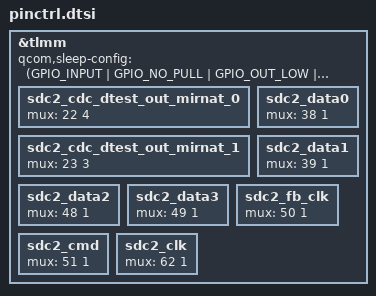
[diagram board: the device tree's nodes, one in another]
#include "gpio-dt.h"

/**
 *
 * NOTE: Every Dev team has to uncomment the respective PIN configuratoin.
 *
 */
&tlmm {
 // qup1_se0_l0: qup1_se0_l0 {
 // mux = <0 1>;
 // };
 // ibi_i3c_qup1_se0_sda: ibi_i3c_qup1_se0_sda {
 // mux = <0 2>;
 // };
 // qup1_se0_l1: qup1_se0_l1 {
 // mux = <1 1>;
 // };
 // ibi_i3c_qup1_se0_scl: ibi_i3c_qup1_se0_scl {
 // mux = <1 2>;
 // };
 // qup1_se0_l2: qup1_se0_l2 {
 // mux = <2 1>;
 // };
 // qup1_se0_l3: qup1_se0_l3 {
 // mux = <3 1>;
 // };
 // qup0_se1_l0: qup0_se1_l0 {
 // mux = <4 1>;
 // };
 // ibi_i3c_qup0_se1_sda: ibi_i3c_qup0_se1_sda {
 // mux = <4 2>;
 // };
 // gcc_gp3_clk_mirb: gcc_gp3_clk_mirb {
 // mux = <4 3>;
 // };
 // qdss_gpio_tracedata_loca_15: qdss_gpio_tracedata_loca_15 {
 // mux = <4 4>;
 // };
 // qup0_se1_l1: qup0_se1_l1 {
 // mux = <5 1>;
 // };
 // ibi_i3c_qup0_se1_scl: ibi_i3c_qup0_se1_scl {
 // mux = <5 2>;
 // };
 // qdss_gpio_tracedata_loca_13: qdss_gpio_tracedata_loca_13 {
 // mux = <5 3>;
 // };
 // qup0_se1_l2: qup0_se1_l2 {
 // mux = <6 1>;
 // };
 // dbg_bus_out_loca_31: dbg_bus_out_loca_31 {
 // mux = <6 2>;
 // };
 // phase_flag_status_loc_31: phase_flag_status_loc_31 {
 // mux = <6 3>;
 // };
 // qup0_se1_l3: qup0_se1_l3 {
 // mux = <7 1>;
 // };
 // dbg_bus_out_loca_30: dbg_bus_out_loca_30 {
 // mux = <7 2>;
 // };
 // phase_flag_status_loc_30: phase_flag_status_loc_30 {
 // mux = <7 3>;
 // };
 // qup0_se2_l0: qup0_se2_l0 {
 // mux = <8 1>;
 // };
 // dbg_bus_out_loca_29: dbg_bus_out_loca_29 {
 // mux = <8 2>;
 // };
 // phase_flag_status_loc_29: phase_flag_status_loc_29 {
 // mux = <8 3>;
 // };
 // qup0_se2_l1: qup0_se2_l1 {
 // mux = <9 1>;
 // };
 // dbg_bus_out_loca_28: dbg_bus_out_loca_28 {
 // mux = <9 2>;
 // };
 // phase_flag_status_loc_28: phase_flag_status_loc_28 {
 // mux = <9 3>;
 // };
 // qup0_se2_l2: qup0_se2_l2 {
 // mux = <10 1>;
 // };
 // dbg_bus_out_loca_27: dbg_bus_out_loca_27 {
 // mux = <10 2>;
 // };
 // phase_flag_status_loc_27: phase_flag_status_loc_27 {
 // mux = <10 3>;
 // };
 // qup0_se2_l3: qup0_se2_l3 {
 // mux = <11 1>;
 // };
 // dbg_bus_out_loca_26: dbg_bus_out_loca_26 {
 // mux = <11 2>;
 // };
 // phase_flag_status_loc_26: phase_flag_status_loc_26 {
 // mux = <11 3>;
 // };
 // cci_timer2: cci_timer2 {
 // mux = <12 1>;
 // };
 // qup0_se3_l0: qup0_se3_l0 {
 // mux = <12 2>;
 // };
 // qup0_se1_l4: qup0_se1_l4 {
 // mux = <12 3>;
 // };
 // dbg_bus_out_loca_25: dbg_bus_out_loca_25 {
 // mux = <12 4>;
 // };
 // phase_flag_status_loc_25: phase_flag_status_loc_25 {
 // mux = <12 5>;
 // };
 // qdss_gpio_tracectl_loca: qdss_gpio_tracectl_loca {
 // mux = <12 6>;
 // };
 // cci_timer3: cci_timer3 {
 // mux = <13 1>;
 // };
 // qup0_se3_l1: qup0_se3_l1 {
 // mux = <13 2>;
 // };
 // qup0_se1_l5: qup0_se1_l5 {
 // mux = <13 3>;
 // };
 // dbg_bus_out_loca_24: dbg_bus_out_loca_24 {
 // mux = <13 4>;
 // };
 // phase_flag_status_loc_24: phase_flag_status_loc_24 {
 // mux = <13 5>;
 // };
 // qdss_gpio_traceclk_loca: qdss_gpio_traceclk_loca {
 // mux = <13 6>;
 // };
 // cci_timer1: cci_timer1 {
 // mux = <14 1>;
 // };
 // cci_async_in2: cci_async_in2 {
 // mux = <14 2>;
 // };
 // qup0_se3_l2: qup0_se3_l2 {
 // mux = <14 3>;
 // };
 // qup0_se1_l6: qup0_se1_l6 {
 // mux = <14 4>;
 // };
 // dbg_bus_out_loca_23: dbg_bus_out_loca_23 {
 // mux = <14 5>;
 // };
 // phase_flag_status_loc_23: phase_flag_status_loc_23 {
 // mux = <14 6>;
 // };
 // cci_timer4: cci_timer4 {
 // mux = <15 1>;
 // };
 // cci_async_in1: cci_async_in1 {
 // mux = <15 2>;
 // };
 // qup0_se3_l3: qup0_se3_l3 {
 // mux = <15 3>;
 // };
 // tgu_ch2_trigout: tgu_ch2_trigout {
 // mux = <15 4>;
 // };
 // dbg_bus_out_loca_22: dbg_bus_out_loca_22 {
 // mux = <15 5>;
 // };
 // phase_flag_status_loc_22: phase_flag_status_loc_22 {
 // mux = <15 6>;
 // };
 // qdss_gpio_tracedata_loca_14: qdss_gpio_tracedata_loca_14 {
 // mux = <15 7>;
 // };
 // qup0_se4_l0: qup0_se4_l0 {
 // mux = <16 1>;
 // };
 // ibi_i3c_qup0_se4_sda: ibi_i3c_qup0_se4_sda {
 // mux = <16 2>;
 // };
 // dbg_bus_out_loca_21: dbg_bus_out_loca_21 {
 // mux = <16 3>;
 // };
 // phase_flag_status_loc_21: phase_flag_status_loc_21 {
 // mux = <16 4>;
 // };
 // qup0_se4_l1: qup0_se4_l1 {
 // mux = <17 1>;
 // };
 // ibi_i3c_qup0_se4_scl: ibi_i3c_qup0_se4_scl {
 // mux = <17 2>;
 // };
 // dbg_bus_out_loca_20: dbg_bus_out_loca_20 {
 // mux = <17 3>;
 // };
 // phase_flag_status_loc_20: phase_flag_status_loc_20 {
 // mux = <17 4>;
 // };
 // qup0_se4_l2: qup0_se4_l2 {
 // mux = <18 1>;
 // };
 // dbg_bus_out_loca_19: dbg_bus_out_loca_19 {
 // mux = <18 2>;
 // };
 // phase_flag_status_loc_19: phase_flag_status_loc_19 {
 // mux = <18 3>;
 // };
 // qup0_se4_l3: qup0_se4_l3 {
 // mux = <19 1>;
 // };
 // gp_pdm_mira_0: gp_pdm_mira_0 {
 // mux = <19 2>;
 // };
 // dbg_bus_out_loca_18: dbg_bus_out_loca_18 {
 // mux = <19 3>;
 // };
 // phase_flag_status_loc_18: phase_flag_status_loc_18 {
 // mux = <19 4>;
 // };
 // qup0_se5_l0: qup0_se5_l0 {
 // mux = <20 1>;
 // };
 // cci_i2c_sda3: cci_i2c_sda3 {
 // mux = <20 2>;
 // };
 // qup0_se2_l4: qup0_se2_l4 {
 // mux = <20 3>;
 // };
 // gp_pdm_mira_1: gp_pdm_mira_1 {
 // mux = <20 4>;
 // };
 // dbg_bus_out_loca_17: dbg_bus_out_loca_17 {
 // mux = <20 5>;
 // };
 // phase_flag_status_loc_17: phase_flag_status_loc_17 {
 // mux = <20 6>;
 // };
 // qup0_se5_l1: qup0_se5_l1 {
 // mux = <21 1>;
 // };
 // cci_i2c_scl3: cci_i2c_scl3 {
 // mux = <21 2>;
 // };
 // qup0_se2_l5: qup0_se2_l5 {
 // mux = <21 3>;
 // };
 // gp_pdm_mira_2: gp_pdm_mira_2 {
 // mux = <21 4>;
 // };
 // dbg_bus_out_loca_16: dbg_bus_out_loca_16 {
 // mux = <21 5>;
 // };
 // phase_flag_status_loc_16: phase_flag_status_loc_16 {
 // mux = <21 6>;
 // };
 // qup0_se5_l2: qup0_se5_l2 {
 // mux = <22 1>;
 // };
 // qup0_se2_l6: qup0_se2_l6 {
 // mux = <22 2>;
 // };
 // jitter_bist_ref_clk: jitter_bist_ref_clk {
 // mux = <22 3>;
 // };
 sdc2_cdc_dtest_out_mirnat_0: sdc2_cdc_dtest_out_mirnat_0 {
 mux = <22 4>;
  };
 // vsense_trigger_mirnat: vsense_trigger_mirnat {
 // mux = <22 5>;
 // };
 // atest_usb0_atereset_mirnat: atest_usb0_atereset_mirnat {
 // mux = <22 6>;
 // };
 // ddr_pxi0_test_tri_mirnat: ddr_pxi0_test_tri_mirnat {
 // mux = <22 7>;
 // };
 // qup0_se5_l3: qup0_se5_l3 {
 // mux = <23 1>;
 // };
 // pll_bist_sync: pll_bist_sync {
 // mux = <23 2>;
 // };
 sdc2_cdc_dtest_out_mirnat_1: sdc2_cdc_dtest_out_mirnat_1 {
 mux = <23 3>;
  };
 // atest_usb0_testdataout0_mirnat_0: atest_usb0_testdataout0_mirnat_0 {
 // mux = <23 4>;
 // };
 // ddr_pxi0_test_done_mirnat: ddr_pxi0_test_done_mirnat {
 // mux = <23 5>;
 // };
 // qup0_se6_l0: qup0_se6_l0 {
 // mux = <24 1>;
 // };
 // ibi_i3c_qup0_se6_sda: ibi_i3c_qup0_se6_sda {
 // mux = <24 2>;
 // };
 // tgu_ch0_trigout: tgu_ch0_trigout {
 // mux = <24 3>;
 // };
 // qdss_cti_trig0_out_mira: qdss_cti_trig0_out_mira {
 // mux = <24 4>;
 // };
 // atest_usb0_testdataout0_mirnat_1: atest_usb0_testdataout0_mirnat_1 {
 // mux = <24 5>;
 // };
 // ddr_pxi1_test_tri_mirnat: ddr_pxi1_test_tri_mirnat {
 // mux = <24 6>;
 // };
 // qup0_se6_l1: qup0_se6_l1 {
 // mux = <25 1>;
 // };
 // ibi_i3c_qup0_se6_scl: ibi_i3c_qup0_se6_scl {
 // mux = <25 2>;
 // };
 // tgu_ch1_trigout: tgu_ch1_trigout {
 // mux = <25 3>;
 // };
 // qdss_cti_trig1_out_mira: qdss_cti_trig1_out_mira {
 // mux = <25 4>;
 // };
 // atest_usb0_testdataout0_mirnat_2: atest_usb0_testdataout0_mirnat_2 {
 // mux = <25 5>;
 // };
 // ddr_pxi1_test_done_mirnat: ddr_pxi1_test_done_mirnat {
 // mux = <25 6>;
 // };
 // qup0_se6_l2: qup0_se6_l2 {
 // mux = <26 1>;
 // };
 // pll_clk_aux: pll_clk_aux {
 // mux = <26 2>;
 // };
 // atest_usb0_testdataout0_mirnat_3: atest_usb0_testdataout0_mirnat_3 {
 // mux = <26 3>;
 // };
 // qup0_se6_l3: qup0_se6_l3 {
 // mux = <27 1>;
 // };
 // gp_mn: gp_mn {
 // mux = <27 2>;
 // };
 // tsense_pwm1_out_mirnat: tsense_pwm1_out_mirnat {
 // mux = <27 3>;
 // };
 // tsense_pwm2_out_mirnat: tsense_pwm2_out_mirnat {
 // mux = <27 4>;
 // };
 // tsense_pwm3_out_mirnat: tsense_pwm3_out_mirnat {
 // mux = <27 5>;
 // };
 // qup0_se7_l0: qup0_se7_l0 {
 // mux = <28 1>;
 // };
 // aoss_cti_debug_data0: aoss_cti_debug_data0 {
 // mux = <28 2>;
 // };
 // tgu_ch3_trigout: tgu_ch3_trigout {
 // mux = <28 3>;
 // };
 // qup0_se7_l1: qup0_se7_l1 {
 // mux = <29 1>;
 // };
 // aoss_cti_debug_data1: aoss_cti_debug_data1 {
 // mux = <29 2>;
 // };
 // sd_write_protect: sd_write_protect {
 // mux = <29 3>;
 // };
 // qup0_se7_l2: qup0_se7_l2 {
 // mux = <30 1>;
 // };
 // cci_async_in0: cci_async_in0 {
 // mux = <30 2>;
 // };
 // aoss_cti_debug_data2: aoss_cti_debug_data2 {
 // mux = <30 3>;
 // };
 // qup0_se7_l3: qup0_se7_l3 {
 // mux = <31 1>;
 // };
 // aoss_cti_debug_data3: aoss_cti_debug_data3 {
 // mux = <31 2>;
 // };
 // qup1_se5_l0: qup1_se5_l0 {
 // mux = <32 1>;
 // };
 // gcc_gp1_clk_mira: gcc_gp1_clk_mira {
 // mux = <32 2>;
 // };
 // gnss_adc_dtest_l1_mirnat_0: gnss_adc_dtest_l1_mirnat_0 {
 // mux = <32 3>;
 // };
 // ddr_pxi2_test_done_mirnat: ddr_pxi2_test_done_mirnat {
 // mux = <32 4>;
 // };
 // qup1_se5_l1: qup1_se5_l1 {
 // mux = <33 1>;
 // };
 // gcc_gp2_clk_mira: gcc_gp2_clk_mira {
 // mux = <33 2>;
 // };
 // gnss_adc_dtest_l1_mirnat_1: gnss_adc_dtest_l1_mirnat_1 {
 // mux = <33 3>;
 // };
 // ddr_pxi2_test_tri_mirnat: ddr_pxi2_test_tri_mirnat {
 // mux = <33 4>;
 // };
 // qup1_se5_l2: qup1_se5_l2 {
 // mux = <34 1>;
 // };
 // gcc_gp3_clk_mira: gcc_gp3_clk_mira {
 // mux = <34 2>;
 // };
 // dbg_out_clk: dbg_out_clk {
 // mux = <34 3>;
 // };
 // gnss_adc_dtest_l5_mirnat_0: gnss_adc_dtest_l5_mirnat_0 {
 // mux = <34 4>;
 // };
 // ddr_pxi3_test_done_mirnat: ddr_pxi3_test_done_mirnat {
 // mux = <34 5>;
 // };
 // qup1_se5_l3: qup1_se5_l3 {
 // mux = <35 1>;
 // };
 // gcc_gp1_clk_mirb: gcc_gp1_clk_mirb {
 // mux = <35 2>;
 // };
 // gnss_adc_dtest_l5_mirnat_1: gnss_adc_dtest_l5_mirnat_1 {
 // mux = <35 3>;
 // };
 // ddr_pxi3_test_tri_mirnat: ddr_pxi3_test_tri_mirnat {
 // mux = <35 4>;
 // };
 // qup1_se1_l0: qup1_se1_l0 {
 // mux = <36 1>;
 // };
 // ibi_i3c_qup1_se1_sda: ibi_i3c_qup1_se1_sda {
 // mux = <36 2>;
 // };
 // qup1_se1_l2: qup1_se1_l2 {
 // mux = <36 3>;
 // };
 // gcc_gp2_clk_mirb: gcc_gp2_clk_mirb {
 // mux = <36 4>;
 // };
 // qup1_se1_l1: qup1_se1_l1 {
 // mux = <37 1>;
 // };
 // ibi_i3c_qup1_se1_scl: ibi_i3c_qup1_se1_scl {
 // mux = <37 2>;
 // };
 // qup1_se1_l3: qup1_se1_l3 {
 // mux = <37 3>;
 // };
 sdc2_data0: sdc2_data0 {
    mux = <38 1>;
  };
 sdc2_data1: sdc2_data1 {
    mux = <39 1>;
  };
 // qup1_se2_l0: qup1_se2_l0 {
 // mux = <40 1>;
 // };
 // dbg_bus_out_loca_13: dbg_bus_out_loca_13 {
 // mux = <40 2>;
 // };
 // phase_flag_status_loc_13: phase_flag_status_loc_13 {
 // mux = <40 3>;
 // };
 // qdss_cti_trig0_in_mirb: qdss_cti_trig0_in_mirb {
 // mux = <40 4>;
 // };
 // qup1_se2_l1: qup1_se2_l1 {
 // mux = <41 1>;
 // };
 // dbg_bus_out_loca_12: dbg_bus_out_loca_12 {
 // mux = <41 2>;
 // };
 // phase_flag_status_loc_12: phase_flag_status_loc_12 {
 // mux = <41 3>;
 // };
 // qdss_cti_trig0_out_mirb: qdss_cti_trig0_out_mirb {
 // mux = <41 4>;
 // };
 // qup1_se2_l2: qup1_se2_l2 {
 // mux = <42 1>;
 // };
 // dbg_bus_out_loca_11: dbg_bus_out_loca_11 {
 // mux = <42 2>;
 // };
 // phase_flag_status_loc_11: phase_flag_status_loc_11 {
 // mux = <42 3>;
 // };
 // qdss_cti_trig1_out_mirb: qdss_cti_trig1_out_mirb {
 // mux = <42 4>;
 // };
 // qup1_se2_l3: qup1_se2_l3 {
 // mux = <43 1>;
 // };
 // gp_pdm_mirb_0: gp_pdm_mirb_0 {
 // mux = <43 2>;
 // };
 // dbg_bus_out_loca_10: dbg_bus_out_loca_10 {
 // mux = <43 3>;
 // };
 // phase_flag_status_loc_10: phase_flag_status_loc_10 {
 // mux = <43 4>;
 // };
 // qdss_cti_trig1_in_mirb: qdss_cti_trig1_in_mirb {
 // mux = <43 5>;
 // };
 // qup1_se3_l0: qup1_se3_l0 {
 // mux = <44 1>;
 // };
 // gp_pdm_mirb_1: gp_pdm_mirb_1 {
 // mux = <44 2>;
 // };
 // dbg_bus_out_loca_9: dbg_bus_out_loca_9 {
 // mux = <44 3>;
 // };
 // phase_flag_status_loc_9: phase_flag_status_loc_9 {
 // mux = <44 4>;
 // };
 // qup1_se3_l1: qup1_se3_l1 {
 // mux = <45 1>;
 // };
 // mdp_vsync_e: mdp_vsync_e {
 // mux = <45 2>;
 // };
 // gp_pdm_mirb_2: gp_pdm_mirb_2 {
 // mux = <45 3>;
 // };
 // dbg_bus_out_loca_8: dbg_bus_out_loca_8 {
 // mux = <45 4>;
 // };
 // phase_flag_status_loc_8: phase_flag_status_loc_8 {
 // mux = <45 5>;
 // };
 // qup1_se3_l2: qup1_se3_l2 {
 // mux = <46 1>;
 // };
 // dbg_bus_out_loca_7: dbg_bus_out_loca_7 {
 // mux = <46 2>;
 // };
 // phase_flag_status_loc_7: phase_flag_status_loc_7 {
 // mux = <46 3>;
 // };
 // qup1_se3_l3: qup1_se3_l3 {
 // mux = <47 1>;
 // };
 // ddr_bist_stop: ddr_bist_stop {
 // mux = <47 2>;
 // };
 // dbg_bus_out_loca_6: dbg_bus_out_loca_6 {
 // mux = <47 3>;
 // };
 // phase_flag_status_loc_6: phase_flag_status_loc_6 {
 // mux = <47 4>;
 // };
 sdc2_data2: sdc2_data2 {
    mux = <48 1>;
  };
 sdc2_data3: sdc2_data3 {
    mux = <49 1>;
  };
 sdc2_fb_clk: sdc2_fb_clk {
    mux = <50 1>;
  };
 sdc2_cmd: sdc2_cmd {
    mux = <51 1>;
  };
 // qup0_se0_l0: qup0_se0_l0 {
 // mux = <52 1>;
 // };
 // dbg_bus_out_locb_7: dbg_bus_out_locb_7 {
 // mux = <52 2>;
 // };
 // qup0_se0_l1: qup0_se0_l1 {
 // mux = <53 1>;
 // };
 // dbg_bus_out_locb_6: dbg_bus_out_locb_6 {
 // mux = <53 2>;
 // };
 // qup0_se0_l2: qup0_se0_l2 {
 // mux = <54 1>;
 // };
 // nav_gpio3: nav_gpio3 {
 // mux = <54 2>;
 // };
 // dbg_bus_out_locb_5: dbg_bus_out_locb_5 {
 // mux = <54 3>;
 // };
 // qup0_se0_l3: qup0_se0_l3 {
 // mux = <55 1>;
 // };
 // dbg_bus_out_locb_4: dbg_bus_out_locb_4 {
 // mux = <55 2>;
 // };
 // qup1_se6_l0: qup1_se6_l0 {
 // mux = <56 1>;
 // };
 // dbg_bus_out_locb_3: dbg_bus_out_locb_3 {
 // mux = <56 2>;
 // };
 // qdss_cti_trig0_in_mira: qdss_cti_trig0_in_mira {
 // mux = <56 3>;
 // };
 // qup1_se6_l1: qup1_se6_l1 {
 // mux = <57 1>;
 // };
 // dbg_bus_out_locb_2: dbg_bus_out_locb_2 {
 // mux = <57 2>;
 // };
 // qup1_se6_l2: qup1_se6_l2 {
 // mux = <58 1>;
 // };
 // dbg_bus_out_locb_1: dbg_bus_out_locb_1 {
 // mux = <58 2>;
 // };
 // qup1_se6_l3: qup1_se6_l3 {
 // mux = <59 1>;
 // };
 // dbg_bus_out_locb_0: dbg_bus_out_locb_0 {
 // mux = <59 2>;
 // };
 // qdss_cti_trig1_in_mira: qdss_cti_trig1_in_mira {
 // mux = <59 3>;
 // };
 // qup1_se7_l0: qup1_se7_l0 {
 // mux = <60 1>;
 // };
 // qup1_se7_l2: qup1_se7_l2 {
 // mux = <60 2>;
 // };
 // qup1_se7_l1: qup1_se7_l1 {
 // mux = <61 1>;
 // };
 // qup1_se7_l3: qup1_se7_l3 {
 // mux = <61 2>;
 // };
 // vfr_0: vfr_0 {
 // mux = <61 3>;
 // };
 // ddr_bist_fail: ddr_bist_fail {
 // mux = <61 4>;
 // };
 // dbg_bus_out_loca_5: dbg_bus_out_loca_5 {
 // mux = <61 5>;
 // };
 // phase_flag_status_loc_5: phase_flag_status_loc_5 {
 // mux = <61 6>;
 // };
 sdc2_clk: sdc2_clk {
    mux = <62 1>;
  };
 // cam_mclk0: cam_mclk0 {
 // mux = <64 1>;
 // };
 // cri_trng_rosc_sync_test_out_0: cri_trng_rosc_sync_test_out_0 {
 // mux = <64 2>;
 // };
 // qdss_gpio_tracedata_loca_0: qdss_gpio_tracedata_loca_0 {
 // mux = <64 3>;
 // };
 // cam_mclk1: cam_mclk1 {
 // mux = <65 1>;
 // };
 // cri_trng_rosc_sync_test_out_1: cri_trng_rosc_sync_test_out_1 {
 // mux = <65 2>;
 // };
 // qdss_gpio_tracedata_loca_1: qdss_gpio_tracedata_loca_1 {
 // mux = <65 3>;
 // };
 // cam_mclk2: cam_mclk2 {
 // mux = <66 1>;
 // };
 // prng_rosc_test_out_0: prng_rosc_test_out_0 {
 // mux = <66 2>;
 // };
 // qdss_gpio_tracedata_loca_2: qdss_gpio_tracedata_loca_2 {
 // mux = <66 3>;
 // };
 // cam_mclk3: cam_mclk3 {
 // mux = <67 1>;
 // };
 // qdss_gpio_tracedata_loca_3: qdss_gpio_tracedata_loca_3 {
 // mux = <67 2>;
 // };
 // cam_aon_mclk4: cam_aon_mclk4 {
 // mux = <68 1>;
 // };
 // prng_rosc_test_out_1: prng_rosc_test_out_1 {
 // mux = <68 2>;
 // };
 // qdss_gpio_tracedata_loca_4: qdss_gpio_tracedata_loca_4 {
 // mux = <68 3>;
 // };
 // cam_mclk5: cam_mclk5 {
 // mux = <69 1>;
 // };
 // tmess_prng_rosc_test_out_3: tmess_prng_rosc_test_out_3 {
 // mux = <69 2>;
 // };
 // qdss_gpio_tracedata_loca_5: qdss_gpio_tracedata_loca_5 {
 // mux = <69 3>;
 // };
 // cci_i2c_sda0: cci_i2c_sda0 {
 // mux = <70 1>;
 // };
 // tmess_prng_rosc_test_out_2: tmess_prng_rosc_test_out_2 {
 // mux = <70 2>;
 // };
 // qdss_gpio_tracedata_loca_6: qdss_gpio_tracedata_loca_6 {
 // mux = <70 3>;
 // };
 // cci_i2c_scl0: cci_i2c_scl0 {
 // mux = <71 1>;
 // };
 // qdss_gpio_tracedata_loca_7: qdss_gpio_tracedata_loca_7 {
 // mux = <71 2>;
 // };
 // cci_i2c_sda1: cci_i2c_sda1 {
 // mux = <72 1>;
 // };
 // tmess_prng_rosc_test_out_1: tmess_prng_rosc_test_out_1 {
 // mux = <72 2>;
 // };
 // qdss_gpio_tracedata_loca_8: qdss_gpio_tracedata_loca_8 {
 // mux = <72 3>;
 // };
 // cci_i2c_scl1: cci_i2c_scl1 {
 // mux = <73 1>;
 // };
 // tmess_prng_rosc_test_out_0: tmess_prng_rosc_test_out_0 {
 // mux = <73 2>;
 // };
 // qdss_gpio_tracedata_loca_9: qdss_gpio_tracedata_loca_9 {
 // mux = <73 3>;
 // };
 // cci_i2c_sda2: cci_i2c_sda2 {
 // mux = <74 1>;
 // };
 // prng_rosc_test_out_3: prng_rosc_test_out_3 {
 // mux = <74 2>;
 // };
 // qdss_gpio_tracedata_loca_10: qdss_gpio_tracedata_loca_10 {
 // mux = <74 3>;
 // };
 // cci_i2c_scl2: cci_i2c_scl2 {
 // mux = <75 1>;
 // };
 // qdss_gpio_tracedata_loca_11: qdss_gpio_tracedata_loca_11 {
 // mux = <75 2>;
 // };
 // cci_timer0: cci_timer0 {
 // mux = <76 1>;
 // };
 // prng_rosc_test_out_2: prng_rosc_test_out_2 {
 // mux = <76 2>;
 // };
 // qdss_gpio_tracedata_loca_12: qdss_gpio_tracedata_loca_12 {
 // mux = <76 3>;
 // };
 // mdp_vsync_p: mdp_vsync_p {
 // mux = <77 1>;
 // };
 // mdp_vsync0_out: mdp_vsync0_out {
 // mux = <77 2>;
 // };
 // mdp_vsync1_out: mdp_vsync1_out {
 // mux = <77 3>;
 // };
 // cri_trng_rosc_test_out: cri_trng_rosc_test_out {
 // mux = <77 4>;
 // };
 // atest_char_status_loc_1: atest_char_status_loc_1 {
 // mux = <77 5>;
 // };
 // mdp_vsync_s: mdp_vsync_s {
 // mux = <78 1>;
 // };
 // mdp_vsync2_out: mdp_vsync2_out {
 // mux = <78 2>;
 // };
 // mdp_vsync3_out: mdp_vsync3_out {
 // mux = <78 3>;
 // };
 // atest_char_status_loc_0: atest_char_status_loc_0 {
 // mux = <78 4>;
 // };
 // qspi0_clk: qspi0_clk {
 // mux = <79 1>;
 // };
 // atest_char_status_loc_3: atest_char_status_loc_3 {
 // mux = <80 1>;
 // };
 // atest_char_status_loc_2: atest_char_status_loc_2 {
 // mux = <81 1>;
 // };
 // coex_uart1_tx: coex_uart1_tx {
 // mux = <82 1>;
 // };
 // usb0_hs_ac_en: usb0_hs_ac_en {
 // mux = <82 2>;
 // };
 // dbg_bus_out_loca_15: dbg_bus_out_loca_15 {
 // mux = <82 3>;
 // };
 // phase_flag_status_loc_15: phase_flag_status_loc_15 {
 // mux = <82 4>;
 // };
 // coex_uart1_rx: coex_uart1_rx {
 // mux = <83 1>;
 // };
 // tb_trig_sdc2: tb_trig_sdc2 {
 // mux = <83 2>;
 // };
 // dbg_bus_out_loca_14: dbg_bus_out_loca_14 {
 // mux = <83 3>;
 // };
 // phase_flag_status_loc_14: phase_flag_status_loc_14 {
 // mux = <83 4>;
 // };
 // uim0_data: uim0_data {
 // mux = <84 1>;
 // };
 // uim0_clk: uim0_clk {
 // mux = <85 1>;
 // };
 // uim0_reset: uim0_reset {
 // mux = <86 1>;
 // };
 // uim0_present: uim0_present {
 // mux = <87 1>;
 // };
 // uim1_data_mirb: uim1_data_mirb {
 // mux = <88 1>;
 // };
 // uim1_clk_mirb: uim1_clk_mirb {
 // mux = <89 1>;
 // };
 // uim1_reset_mirb: uim1_reset_mirb {
 // mux = <90 1>;
 // };
 // uim1_present_mirb: uim1_present_mirb {
 // mux = <91 1>;
 // };
 // qlink_little_request: qlink_little_request {
 // mux = <92 1>;
 // };
 // qlink_little_enable: qlink_little_enable {
 // mux = <93 1>;
 // };
 // qlink_wmss_reset_n: qlink_wmss_reset_n {
 // mux = <94 1>;
 // };
 // qlink_big_request: qlink_big_request {
 // mux = <95 1>;
 // };
 // qlink_big_enable: qlink_big_enable {
 // mux = <96 1>;
 // };
 // uim1_data_mira: uim1_data_mira {
 // mux = <97 1>;
 // };
 // qspi0_data_0: qspi0_data_0 {
 // mux = <97 2>;
 // };
 // uim1_clk_mira: uim1_clk_mira {
 // mux = <98 1>;
 // };
 // qspi0_data_1: qspi0_data_1 {
 // mux = <98 2>;
 // };
 // uim1_reset_mira: uim1_reset_mira {
 // mux = <99 1>;
 // };
 // qspi0_data_2: qspi0_data_2 {
 // mux = <99 2>;
 // };
 // uim1_present_mira: uim1_present_mira {
 // mux = <100 1>;
 // };
 // qspi0_data_3: qspi0_data_3 {
 // mux = <100 2>;
 // };
 // rffe0_clk: rffe0_clk {
 // mux = <101 1>;
 // };
 // grfc0: grfc0 {
 // mux = <101 2>;
 // };
 // rffe0_data: rffe0_data {
 // mux = <102 1>;
 // };
 // grfc1: grfc1 {
 // mux = <102 2>;
 // };
 // rffe1_clk: rffe1_clk {
 // mux = <103 1>;
 // };
 // grfc2: grfc2 {
 // mux = <103 2>;
 // };
 // rffe1_data: rffe1_data {
 // mux = <104 1>;
 // };
 // grfc3: grfc3 {
 // mux = <104 2>;
 // };
 // rffe2_clk: rffe2_clk {
 // mux = <105 1>;
 // };
 // grfc4: grfc4 {
 // mux = <105 2>;
 // };
 // rffe2_data: rffe2_data {
 // mux = <106 1>;
 // };
 // grfc5: grfc5 {
 // mux = <106 2>;
 // };
 // grfc6: grfc6 {
 // mux = <107 1>;
 // };
 // grfc7: grfc7 {
 // mux = <108 1>;
 // };
 // grfc8: grfc8 {
 // mux = <109 1>;
 // };
 // grfc9: grfc9 {
 // mux = <110 1>;
 // };
 // grfc10: grfc10 {
 // mux = <111 1>;
 // };
 // coex_uart2_rx: coex_uart2_rx {
 // mux = <111 2>;
 // };
 // grfc11: grfc11 {
 // mux = <112 1>;
 // };
 // coex_uart2_tx: coex_uart2_tx {
 // mux = <112 2>;
 // };
 // nav_gpio0: nav_gpio0 {
 // mux = <113 1>;
 // };
 // vfr_1: vfr_1 {
 // mux = <113 2>;
 // };
 // nav_gpio1: nav_gpio1 {
 // mux = <114 1>;
 // };
 // nav_gpio2: nav_gpio2 {
 // mux = <115 1>;
 // };
 // grfc12: grfc12 {
 // mux = <115 2>;
 // };
 // qspi0_cs0_n: qspi0_cs0_n {
 // mux = <116 1>;
 // };
 // dbg_bus_out_loca_2: dbg_bus_out_loca_2 {
 // mux = <117 1>;
 // };
 // phase_flag_status_loc_2: phase_flag_status_loc_2 {
 // mux = <117 2>;
 // };
 // atest_char_start: atest_char_start {
 // mux = <117 3>;
 // };
 // pcie0_clk_req_n: pcie0_clk_req_n {
 // mux = <118 1>;
 // };
 // dbg_bus_out_loca_1: dbg_bus_out_loca_1 {
 // mux = <118 2>;
 // };
 // phase_flag_status_loc_1: phase_flag_status_loc_1 {
 // mux = <118 3>;
 // };
 // usb0_phy_ps: usb0_phy_ps {
 // mux = <122 1>;
 // };
 // dbg_bus_out_loca_0: dbg_bus_out_loca_0 {
 // mux = <122 2>;
 // };
 // phase_flag_status_loc_0: phase_flag_status_loc_0 {
 // mux = <122 3>;
 // };
 // i2s1_sck: i2s1_sck {
 // mux = <123 1>;
 // };
 // qdss_gpio_tracedata_locb_4: qdss_gpio_tracedata_locb_4 {
 // mux = <123 2>;
 // };
 // i2s1_data0: i2s1_data0 {
 // mux = <124 1>;
 // };
 // qdss_gpio_tracedata_locb_10: qdss_gpio_tracedata_locb_10 {
 // mux = <124 2>;
 // };
 // i2s1_ws: i2s1_ws {
 // mux = <125 1>;
 // };
 // qdss_gpio_tracedata_locb_14: qdss_gpio_tracedata_locb_14 {
 // mux = <125 2>;
 // };
 // i2s1_data1: i2s1_data1 {
 // mux = <126 1>;
 // };
 // audio_ext_mclk1: audio_ext_mclk1 {
 // mux = <126 2>;
 // };
 // audio_ref_clk: audio_ref_clk {
 // mux = <126 3>;
 // };
 // audio_ext_mclk0: audio_ext_mclk0 {
 // mux = <127 1>;
 // };
 // dp0_hot_plug_detect: dp0_hot_plug_detect {
 // mux = <127 2>;
 // };
 // i2s0_sck: i2s0_sck {
 // mux = <128 1>;
 // };
 // i2s0_ws: i2s0_ws {
 // mux = <129 1>;
 // };
 // i2s0_data0: i2s0_data0 {
 // mux = <130 1>;
 // };
 // i2s0_data1: i2s0_data1 {
 // mux = <131 1>;
 // };
 // host2wlan_sol: host2wlan_sol {
 // mux = <132 1>;
 // };
 // resout_gpio_n: resout_gpio_n {
 // mux = <133 1>;
 // };
 // ddr_bist_start: ddr_bist_start {
 // mux = <133 2>;
 // };
 // dbg_bus_out_loca_4: dbg_bus_out_loca_4 {
 // mux = <133 3>;
 // };
 // phase_flag_status_loc_4: phase_flag_status_loc_4 {
 // mux = <133 4>;
 // };
 // dbg_bus_out_locb_31: dbg_bus_out_locb_31 {
 // mux = <135 1>;
 // };
 // dbg_bus_out_locb_30: dbg_bus_out_locb_30 {
 // mux = <136 1>;
 // };
 // ddr_bist_complete: ddr_bist_complete {
 // mux = <137 1>;
 // };
 // dbg_bus_out_loca_3: dbg_bus_out_loca_3 {
 // mux = <137 2>;
 // };
 // phase_flag_status_loc_3: phase_flag_status_loc_3 {
 // mux = <137 3>;
 // };
 // qspi0_cs1_n: qspi0_cs1_n {
 // mux = <138 1>;
 // };
 // dbg_bus_out_locb_28: dbg_bus_out_locb_28 {
 // mux = <138 2>;
 // };
 // dbg_bus_out_locb_27: dbg_bus_out_locb_27 {
 // mux = <139 1>;
 // };
 // dbg_bus_out_locb_26: dbg_bus_out_locb_26 {
 // mux = <140 1>;
 // };
 // dbg_bus_out_locb_25: dbg_bus_out_locb_25 {
 // mux = <141 1>;
 // };
 // dbg_bus_out_locb_24: dbg_bus_out_locb_24 {
 // mux = <142 1>;
 // };
 // dbg_bus_out_locb_23: dbg_bus_out_locb_23 {
 // mux = <143 1>;
 // };
 // dbg_bus_out_locb_22: dbg_bus_out_locb_22 {
 // mux = <144 1>;
 // };
 // dbg_bus_out_locb_21: dbg_bus_out_locb_21 {
 // mux = <145 1>;
 // };
 // dbg_bus_out_locb_20: dbg_bus_out_locb_20 {
 // mux = <146 1>;
 // };
 // dbg_bus_out_locb_19: dbg_bus_out_locb_19 {
 // mux = <147 1>;
 // };
 // dbg_bus_out_locb_18: dbg_bus_out_locb_18 {
 // mux = <148 1>;
 // };
 // dbg_bus_out_locb_17: dbg_bus_out_locb_17 {
 // mux = <149 1>;
 // };
 // dbg_bus_out_locb_16: dbg_bus_out_locb_16 {
 // mux = <150 1>;
 // };
 // dbg_bus_out_locb_15: dbg_bus_out_locb_15 {
 // mux = <151 1>;
 // };
 // dbg_bus_out_locb_14: dbg_bus_out_locb_14 {
 // mux = <152 1>;
 // };
 // dbg_bus_out_locb_13: dbg_bus_out_locb_13 {
 // mux = <153 1>;
 // };
 // dbg_bus_out_locb_12: dbg_bus_out_locb_12 {
 // mux = <154 1>;
 // };
 // dbg_bus_out_locb_11: dbg_bus_out_locb_11 {
 // mux = <155 1>;
 // };
 // dbg_bus_out_locb_10: dbg_bus_out_locb_10 {
 // mux = <156 1>;
 // };
 // dbg_bus_out_locb_9: dbg_bus_out_locb_9 {
 // mux = <157 1>;
 // };
 // dbg_bus_out_locb_8: dbg_bus_out_locb_8 {
 // mux = <158 1>;
 // };
 // dbg_bus_out_locb_29: dbg_bus_out_locb_29 {
 // mux = <159 1>;
 // };
 // qdss_gpio_tracedata_locb_0: qdss_gpio_tracedata_locb_0 {
 // mux = <160 1>;
 // };
 // qdss_gpio_tracedata_locb_1: qdss_gpio_tracedata_locb_1 {
 // mux = <161 1>;
 // };
 // qdss_gpio_tracedata_locb_2: qdss_gpio_tracedata_locb_2 {
 // mux = <162 1>;
 // };
 // qdss_gpio_tracedata_locb_3: qdss_gpio_tracedata_locb_3 {
 // mux = <163 1>;
 // };
 // qdss_gpio_traceclk_locb: qdss_gpio_traceclk_locb {
 // mux = <164 1>;
 // };
 // qdss_gpio_tracedata_locb_5: qdss_gpio_tracedata_locb_5 {
 // mux = <165 1>;
 // };
 // qdss_gpio_tracedata_locb_6: qdss_gpio_tracedata_locb_6 {
 // mux = <166 1>;
 // };
 // qdss_gpio_tracedata_locb_7: qdss_gpio_tracedata_locb_7 {
 // mux = <167 1>;
 // };
 // qdss_gpio_tracedata_locb_8: qdss_gpio_tracedata_locb_8 {
 // mux = <168 1>;
 // };
 // qdss_gpio_tracedata_locb_9: qdss_gpio_tracedata_locb_9 {
 // mux = <169 1>;
 // };
 // qdss_gpio_tracedata_locb_11: qdss_gpio_tracedata_locb_11 {
 // mux = <171 1>;
 // };
 // qdss_gpio_tracedata_locb_12: qdss_gpio_tracedata_locb_12 {
 // mux = <172 1>;
 // };
 // qdss_gpio_tracedata_locb_13: qdss_gpio_tracedata_locb_13 {
 // mux = <173 1>;
 // };
 // qdss_gpio_tracectl_locb: qdss_gpio_tracectl_locb {
 // mux = <174 1>;
 // };
 // qdss_gpio_tracedata_locb_15: qdss_gpio_tracedata_locb_15 {
 // mux = <175 1>;
 // };
 // qup1_se4_l0: qup1_se4_l0 {
 // mux = <176 1>;
 // };
 // qup1_se4_l2: qup1_se4_l2 {
 // mux = <176 2>;
 // };
 // qup1_se4_l1: qup1_se4_l1 {
 // mux = <177 1>;
 // };
 // qup1_se4_l3: qup1_se4_l3 {
 // mux = <177 2>;
 // };
};


&tlmm {
  qcom,sleep-config   =  <
(GPIO_INPUT | GPIO_NO_PULL | GPIO_OUT_LOW | GPIO_PRG_NO)
(GPIO_INPUT | GPIO_NO_PULL | GPIO_OUT_LOW | GPIO_PRG_NO)
(GPIO_INPUT | GPIO_NO_PULL | GPIO_OUT_LOW | GPIO_PRG_NO)
(GPIO_INPUT | GPIO_NO_PULL | GPIO_OUT_LOW | GPIO_PRG_NO)
(GPIO_INPUT | GPIO_PULL_DOWN | GPIO_OUT_LOW | GPIO_PRG_NO)
(GPIO_INPUT | GPIO_PULL_DOWN | GPIO_OUT_LOW | GPIO_PRG_NO)
(GPIO_INPUT | GPIO_PULL_DOWN | GPIO_OUT_LOW | GPIO_PRG_NO)
(GPIO_INPUT | GPIO_PULL_DOWN | GPIO_OUT_LOW | GPIO_PRG_NO)
(GPIO_INPUT | GPIO_PULL_DOWN | GPIO_OUT_LOW | GPIO_PRG_NO)
(GPIO_INPUT | GPIO_PULL_DOWN | GPIO_OUT_LOW | GPIO_PRG_NO)

(GPIO_INPUT | GPIO_PULL_DOWN | GPIO_OUT_LOW | GPIO_PRG_NO)
(GPIO_INPUT | GPIO_PULL_DOWN | GPIO_OUT_LOW | GPIO_PRG_NO)
(GPIO_INPUT | GPIO_PULL_DOWN | GPIO_OUT_LOW | GPIO_PRG_NO)
(GPIO_INPUT | GPIO_PULL_DOWN | GPIO_OUT_LOW | GPIO_PRG_NO)
(GPIO_INPUT | GPIO_PULL_DOWN | GPIO_OUT_LOW | GPIO_PRG_NO)
(GPIO_INPUT | GPIO_PULL_DOWN | GPIO_OUT_LOW | GPIO_PRG_NO)
(GPIO_OUTPUT | GPIO_PULL_UP | GPIO_OUT_HIGH | GPIO_PRG_YES)
(GPIO_OUTPUT | GPIO_PULL_UP | GPIO_OUT_HIGH | GPIO_PRG_YES)
(GPIO_INPUT | GPIO_PULL_DOWN | GPIO_OUT_LOW | GPIO_PRG_NO)
(GPIO_INPUT | GPIO_PULL_DOWN | GPIO_OUT_LOW | GPIO_PRG_NO)

(GPIO_INPUT | GPIO_PULL_DOWN | GPIO_OUT_LOW | GPIO_PRG_NO)
(GPIO_INPUT | GPIO_PULL_DOWN | GPIO_OUT_LOW | GPIO_PRG_NO)
(GPIO_OUTPUT | GPIO_PULL_UP | GPIO_OUT_HIGH | GPIO_PRG_YES)
(GPIO_INPUT | GPIO_PULL_DOWN | GPIO_OUT_LOW | GPIO_PRG_NO)
(GPIO_INPUT | GPIO_PULL_DOWN | GPIO_OUT_LOW | GPIO_PRG_NO)
(GPIO_INPUT | GPIO_PULL_DOWN | GPIO_OUT_LOW | GPIO_PRG_NO)
(GPIO_INPUT | GPIO_PULL_DOWN | GPIO_OUT_LOW | GPIO_PRG_NO)
(GPIO_INPUT | GPIO_PULL_DOWN | GPIO_OUT_LOW | GPIO_PRG_NO)
(GPIO_INPUT | GPIO_PULL_DOWN | GPIO_OUT_LOW | GPIO_PRG_NO)
(GPIO_INPUT | GPIO_PULL_DOWN | GPIO_OUT_LOW | GPIO_PRG_NO)

(GPIO_INPUT | GPIO_PULL_DOWN | GPIO_OUT_LOW | GPIO_PRG_NO)
(GPIO_INPUT | GPIO_NO_PULL | GPIO_OUT_LOW | GPIO_PRG_YES)
(GPIO_INPUT | GPIO_NO_PULL | GPIO_OUT_LOW | GPIO_PRG_YES)
(GPIO_INPUT | GPIO_PULL_DOWN | GPIO_OUT_LOW | GPIO_PRG_NO)
(GPIO_INPUT | GPIO_PULL_DOWN | GPIO_OUT_LOW | GPIO_PRG_NO)
(GPIO_INPUT | GPIO_PULL_DOWN | GPIO_OUT_LOW | GPIO_PRG_NO)
(GPIO_OUTPUT | GPIO_PULL_UP | GPIO_OUT_HIGH | GPIO_PRG_YES)
(GPIO_OUTPUT | GPIO_PULL_UP | GPIO_OUT_HIGH | GPIO_PRG_YES)
(GPIO_INPUT | GPIO_PULL_DOWN | GPIO_OUT_LOW | GPIO_PRG_NO)
(GPIO_INPUT | GPIO_PULL_DOWN | GPIO_OUT_LOW | GPIO_PRG_NO)

(GPIO_INPUT | GPIO_PULL_DOWN | GPIO_OUT_LOW | GPIO_PRG_NO)
(GPIO_INPUT | GPIO_PULL_DOWN | GPIO_OUT_LOW | GPIO_PRG_NO)
(GPIO_OUTPUT | GPIO_PULL_UP | GPIO_OUT_HIGH | GPIO_PRG_YES)
(GPIO_INPUT | GPIO_PULL_DOWN | GPIO_OUT_LOW | GPIO_PRG_NO)
(GPIO_OUTPUT | GPIO_PULL_UP | GPIO_OUT_HIGH | GPIO_PRG_YES)
(GPIO_OUTPUT | GPIO_PULL_UP | GPIO_OUT_HIGH | GPIO_PRG_YES)
(GPIO_INPUT | GPIO_PULL_DOWN | GPIO_OUT_LOW | GPIO_PRG_NO)
(GPIO_INPUT | GPIO_PULL_DOWN | GPIO_OUT_LOW | GPIO_PRG_NO)
(GPIO_INPUT | GPIO_PULL_DOWN | GPIO_OUT_LOW | GPIO_PRG_NO)
(GPIO_INPUT | GPIO_PULL_DOWN | GPIO_OUT_LOW | GPIO_PRG_NO)

(GPIO_INPUT | GPIO_PULL_DOWN | GPIO_OUT_LOW | GPIO_PRG_NO)
(GPIO_INPUT | GPIO_PULL_DOWN | GPIO_OUT_LOW | GPIO_PRG_NO)
(GPIO_OUTPUT | GPIO_PULL_UP | GPIO_OUT_HIGH | GPIO_PRG_YES)
(GPIO_OUTPUT | GPIO_PULL_UP | GPIO_OUT_HIGH | GPIO_PRG_YES)
(GPIO_INPUT | GPIO_PULL_DOWN | GPIO_OUT_LOW | GPIO_PRG_NO)
(GPIO_INPUT | GPIO_PULL_DOWN | GPIO_OUT_LOW | GPIO_PRG_NO)
(GPIO_OUTPUT | GPIO_PULL_UP | GPIO_OUT_HIGH | GPIO_PRG_YES)
(GPIO_OUTPUT | GPIO_PULL_UP | GPIO_OUT_HIGH | GPIO_PRG_YES)
(GPIO_OUTPUT | GPIO_PULL_UP | GPIO_OUT_HIGH | GPIO_PRG_YES)
(GPIO_OUTPUT | GPIO_PULL_UP | GPIO_OUT_HIGH| GPIO_PRG_YES)

(GPIO_INPUT | GPIO_PULL_DOWN | GPIO_OUT_LOW | GPIO_PRG_NO)
(GPIO_INPUT | GPIO_PULL_DOWN | GPIO_OUT_LOW | GPIO_PRG_NO)
(GPIO_INPUT | GPIO_PULL_DOWN | GPIO_OUT_LOW | GPIO_PRG_NO)
(GPIO_INPUT | GPIO_PULL_DOWN | GPIO_OUT_LOW | GPIO_PRG_NO)
(GPIO_INPUT | GPIO_PULL_DOWN | GPIO_OUT_LOW | GPIO_PRG_NO)
(GPIO_INPUT | GPIO_PULL_DOWN | GPIO_OUT_LOW | GPIO_PRG_NO)
(GPIO_INPUT | GPIO_PULL_DOWN | GPIO_OUT_LOW | GPIO_PRG_NO)
(GPIO_INPUT | GPIO_PULL_DOWN | GPIO_OUT_LOW | GPIO_PRG_NO)
(GPIO_INPUT | GPIO_PULL_DOWN | GPIO_OUT_LOW | GPIO_PRG_NO)
(GPIO_INPUT | GPIO_PULL_DOWN | GPIO_OUT_LOW | GPIO_PRG_NO)

(GPIO_INPUT | GPIO_PULL_DOWN | GPIO_OUT_LOW | GPIO_PRG_NO)
(GPIO_INPUT | GPIO_PULL_DOWN | GPIO_OUT_LOW | GPIO_PRG_NO)
(GPIO_INPUT | GPIO_PULL_DOWN | GPIO_OUT_LOW | GPIO_PRG_NO)
(GPIO_INPUT | GPIO_PULL_DOWN | GPIO_OUT_LOW | GPIO_PRG_NO)
(GPIO_INPUT | GPIO_PULL_DOWN | GPIO_OUT_LOW | GPIO_PRG_NO)
(GPIO_INPUT | GPIO_PULL_DOWN | GPIO_OUT_LOW | GPIO_PRG_NO)
(GPIO_INPUT | GPIO_PULL_DOWN | GPIO_OUT_LOW | GPIO_PRG_NO)
(GPIO_INPUT | GPIO_PULL_DOWN | GPIO_OUT_LOW | GPIO_PRG_NO)
(GPIO_INPUT | GPIO_PULL_DOWN | GPIO_OUT_LOW | GPIO_PRG_NO)
(GPIO_INPUT | GPIO_PULL_DOWN | GPIO_OUT_LOW | GPIO_PRG_NO)

(GPIO_INPUT | GPIO_PULL_DOWN | GPIO_OUT_LOW | GPIO_PRG_NO)
(GPIO_OUTPUT | GPIO_PULL_UP | GPIO_OUT_HIGH | GPIO_PRG_YES)
(GPIO_OUTPUT | GPIO_PULL_UP | GPIO_OUT_HIGH | GPIO_PRG_YES)
(GPIO_INPUT | GPIO_PULL_DOWN | GPIO_OUT_LOW | GPIO_PRG_NO)
(GPIO_INPUT | GPIO_PULL_DOWN | GPIO_OUT_LOW | GPIO_PRG_NO)
(GPIO_INPUT | GPIO_PULL_DOWN | GPIO_OUT_LOW | GPIO_PRG_NO)
(GPIO_INPUT | GPIO_PULL_DOWN | GPIO_OUT_LOW | GPIO_PRG_NO)
(GPIO_INPUT | GPIO_PULL_DOWN | GPIO_OUT_LOW | GPIO_PRG_NO)
(GPIO_OUTPUT | GPIO_NO_PULL | GPIO_OUT_LOW | GPIO_PRG_YES)
(GPIO_OUTPUT | GPIO_NO_PULL | GPIO_OUT_LOW | GPIO_PRG_YES)

(GPIO_OUTPUT| GPIO_NO_PULL | GPIO_OUT_LOW | GPIO_PRG_YES)
(GPIO_INPUT | GPIO_PULL_DOWN | GPIO_OUT_LOW | GPIO_PRG_NO)
(GPIO_INPUT | GPIO_NO_PULL | GPIO_OUT_LOW | GPIO_PRG_YES)
(GPIO_INPUT | GPIO_NO_PULL | GPIO_OUT_LOW | GPIO_PRG_YES)
(GPIO_INPUT | GPIO_NO_PULL | GPIO_OUT_LOW | GPIO_PRG_YES)
(GPIO_INPUT | GPIO_NO_PULL | GPIO_OUT_LOW | GPIO_PRG_YES)
(GPIO_INPUT | GPIO_NO_PULL | GPIO_OUT_LOW | GPIO_PRG_YES)
(GPIO_INPUT | GPIO_NO_PULL | GPIO_OUT_LOW | GPIO_PRG_YES)
(GPIO_INPUT | GPIO_NO_PULL | GPIO_OUT_LOW | GPIO_PRG_YES)
(GPIO_INPUT | GPIO_NO_PULL | GPIO_OUT_LOW | GPIO_PRG_YES)

(GPIO_INPUT | GPIO_PULL_DOWN | GPIO_OUT_LOW | GPIO_PRG_NO)
(GPIO_INPUT | GPIO_PULL_DOWN | GPIO_OUT_LOW | GPIO_PRG_NO)
(GPIO_INPUT | GPIO_PULL_DOWN | GPIO_OUT_LOW | GPIO_PRG_NO)
(GPIO_INPUT | GPIO_PULL_DOWN | GPIO_OUT_LOW | GPIO_PRG_NO)
(GPIO_INPUT | GPIO_PULL_DOWN | GPIO_OUT_LOW | GPIO_PRG_NO)
(GPIO_INPUT | GPIO_PULL_DOWN | GPIO_OUT_LOW | GPIO_PRG_NO)
(GPIO_INPUT | GPIO_PULL_DOWN | GPIO_OUT_LOW | GPIO_PRG_NO)
(GPIO_INPUT | GPIO_PULL_DOWN | GPIO_OUT_LOW | GPIO_PRG_NO)
(GPIO_INPUT | GPIO_PULL_DOWN | GPIO_OUT_LOW | GPIO_PRG_NO)
(GPIO_INPUT | GPIO_PULL_DOWN | GPIO_OUT_LOW | GPIO_PRG_NO)

(GPIO_INPUT | GPIO_PULL_DOWN | GPIO_OUT_LOW | GPIO_PRG_NO)
(GPIO_INPUT | GPIO_PULL_DOWN | GPIO_OUT_LOW | GPIO_PRG_NO)
(GPIO_INPUT | GPIO_PULL_DOWN | GPIO_OUT_LOW | GPIO_PRG_NO)
(GPIO_INPUT | GPIO_PULL_DOWN | GPIO_OUT_LOW | GPIO_PRG_NO)
(GPIO_INPUT | GPIO_PULL_DOWN | GPIO_OUT_LOW | GPIO_PRG_NO)
(GPIO_INPUT | GPIO_PULL_DOWN | GPIO_OUT_LOW | GPIO_PRG_NO)
(GPIO_INPUT | GPIO_PULL_DOWN | GPIO_OUT_LOW | GPIO_PRG_NO)
(GPIO_INPUT | GPIO_NO_PULL | GPIO_OUT_LOW | GPIO_PRG_YES)
(GPIO_OUTPUT | GPIO_PULL_UP | GPIO_OUT_HIGH | GPIO_PRG_YES)
(GPIO_INPUT | GPIO_PULL_DOWN | GPIO_OUT_LOW | GPIO_PRG_NO)

(GPIO_INPUT | GPIO_PULL_DOWN | GPIO_OUT_LOW | GPIO_PRG_NO)
(GPIO_INPUT | GPIO_PULL_DOWN | GPIO_OUT_LOW | GPIO_PRG_NO)
(GPIO_INPUT | GPIO_PULL_DOWN | GPIO_OUT_LOW | GPIO_PRG_NO)
(GPIO_INPUT | GPIO_PULL_DOWN | GPIO_OUT_LOW | GPIO_PRG_NO)
(GPIO_INPUT | GPIO_PULL_DOWN | GPIO_OUT_LOW | GPIO_PRG_NO)
(GPIO_INPUT | GPIO_PULL_DOWN | GPIO_OUT_LOW | GPIO_PRG_NO)
(GPIO_INPUT | GPIO_PULL_DOWN | GPIO_OUT_LOW | GPIO_PRG_NO)
(GPIO_INPUT | GPIO_PULL_DOWN | GPIO_OUT_LOW | GPIO_PRG_NO)
(GPIO_INPUT | GPIO_PULL_DOWN | GPIO_OUT_LOW | GPIO_PRG_NO)
(GPIO_INPUT | GPIO_PULL_DOWN | GPIO_OUT_LOW | GPIO_PRG_NO)

(GPIO_INPUT | GPIO_PULL_UP | GPIO_OUT_HIGH | GPIO_PRG_YES)
(GPIO_INPUT | GPIO_PULL_DOWN | GPIO_OUT_LOW | GPIO_PRG_NO)
(GPIO_INPUT | GPIO_NO_PULL | GPIO_OUT_LOW| GPIO_PRG_YES)
(GPIO_INPUT | GPIO_NO_PULL | GPIO_OUT_LOW | GPIO_PRG_YES)
(GPIO_INPUT | GPIO_PULL_DOWN | GPIO_OUT_LOW | GPIO_PRG_NO)
(GPIO_INPUT | GPIO_NO_PULL | GPIO_OUT_LOW | GPIO_PRG_YES)
(GPIO_INPUT | GPIO_NO_PULL | GPIO_OUT_LOW | GPIO_PRG_YES)
(GPIO_INPUT | GPIO_PULL_DOWN | GPIO_OUT_LOW | GPIO_PRG_NO)
(GPIO_INPUT | GPIO_PULL_DOWN | GPIO_OUT_LOW | GPIO_PRG_NO)
(GPIO_INPUT | GPIO_PULL_DOWN | GPIO_OUT_LOW | GPIO_PRG_NO)

(GPIO_INPUT | GPIO_PULL_DOWN | GPIO_OUT_LOW | GPIO_PRG_NO)
(GPIO_INPUT | GPIO_PULL_DOWN | GPIO_OUT_LOW | GPIO_PRG_NO)
(GPIO_INPUT | GPIO_PULL_DOWN | GPIO_OUT_LOW | GPIO_PRG_NO)
(GPIO_INPUT | GPIO_PULL_DOWN | GPIO_OUT_LOW | GPIO_PRG_NO)
(GPIO_INPUT | GPIO_PULL_DOWN | GPIO_OUT_LOW | GPIO_PRG_NO)
(GPIO_INPUT | GPIO_PULL_DOWN | GPIO_OUT_LOW | GPIO_PRG_NO)
(GPIO_INPUT | GPIO_PULL_DOWN | GPIO_OUT_LOW | GPIO_PRG_NO)
(GPIO_INPUT | GPIO_PULL_DOWN | GPIO_OUT_LOW | GPIO_PRG_NO)
(GPIO_INPUT | GPIO_PULL_DOWN | GPIO_OUT_LOW | GPIO_PRG_NO)
(GPIO_INPUT | GPIO_PULL_DOWN | GPIO_OUT_LOW | GPIO_PRG_NO)

(GPIO_INPUT | GPIO_PULL_DOWN | GPIO_OUT_LOW | GPIO_PRG_NO)
(GPIO_INPUT | GPIO_PULL_DOWN | GPIO_OUT_LOW | GPIO_PRG_NO)
(GPIO_INPUT | GPIO_PULL_DOWN | GPIO_OUT_LOW | GPIO_PRG_NO)
(GPIO_INPUT | GPIO_PULL_DOWN | GPIO_OUT_LOW | GPIO_PRG_NO)
(GPIO_INPUT | GPIO_PULL_DOWN | GPIO_OUT_LOW | GPIO_PRG_NO)
(GPIO_INPUT | GPIO_PULL_DOWN | GPIO_OUT_LOW | GPIO_PRG_NO)
(GPIO_INPUT | GPIO_PULL_DOWN | GPIO_OUT_LOW | GPIO_PRG_NO)
(GPIO_INPUT | GPIO_PULL_DOWN | GPIO_OUT_LOW | GPIO_PRG_NO)
(GPIO_INPUT | GPIO_KEEPER | GPIO_OUT_LOW | GPIO_PRG_NO)
(GPIO_INPUT | GPIO_KEEPER | GPIO_OUT_LOW | GPIO_PRG_NO)

(GPIO_INPUT | GPIO_NO_PULL | GPIO_OUT_LOW | GPIO_PRG_NO)
(GPIO_INPUT | GPIO_NO_PULL | GPIO_OUT_LOW | GPIO_PRG_NO)
(GPIO_INPUT | GPIO_KEEPER | GPIO_OUT_LOW | GPIO_PRG_NO)
(GPIO_INPUT | GPIO_KEEPER | GPIO_OUT_LOW | GPIO_PRG_NO)
(GPIO_INPUT | GPIO_KEEPER | GPIO_OUT_LOW | GPIO_PRG_NO)
(GPIO_INPUT | GPIO_KEEPER | GPIO_OUT_LOW | GPIO_PRG_NO)
(GPIO_INPUT | GPIO_NO_PULL | GPIO_OUT_LOW | GPIO_PRG_NO)
(GPIO_INPUT | GPIO_NO_PULL | GPIO_OUT_LOW | GPIO_PRG_NO)
(GPIO_INPUT | GPIO_PULL_DOWN | GPIO_OUT_LOW | GPIO_PRG_NO)
(GPIO_INPUT | GPIO_PULL_DOWN | GPIO_OUT_LOW | GPIO_PRG_NO)

(GPIO_INPUT | GPIO_PULL_DOWN | GPIO_OUT_LOW | GPIO_PRG_NO)
(GPIO_INPUT | GPIO_PULL_DOWN | GPIO_OUT_LOW | GPIO_PRG_NO)
(GPIO_INPUT | GPIO_PULL_UP | GPIO_OUT_HIGH | GPIO_PRG_NO)
(GPIO_INPUT | GPIO_PULL_DOWN | GPIO_OUT_LOW | GPIO_PRG_NO)
(GPIO_INPUT | GPIO_PULL_DOWN | GPIO_OUT_LOW | GPIO_PRG_NO)
(GPIO_INPUT | GPIO_PULL_DOWN | GPIO_OUT_LOW | GPIO_PRG_NO)
(GPIO_INPUT | GPIO_PULL_DOWN | GPIO_OUT_LOW | GPIO_PRG_NO)
(GPIO_INPUT | GPIO_PULL_DOWN | GPIO_OUT_LOW | GPIO_PRG_NO)
  >;
};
